# BL808 register map
File version: 0.1
Registers are access not given, no defined reset value unless marked. A register's access mark holds for its fields unless they carry their own. Offsets are from the block's base; [hi:lo] are bit positions; {n}, {i} and the like mark numbered series.

## DSP2
Base 0x30011000
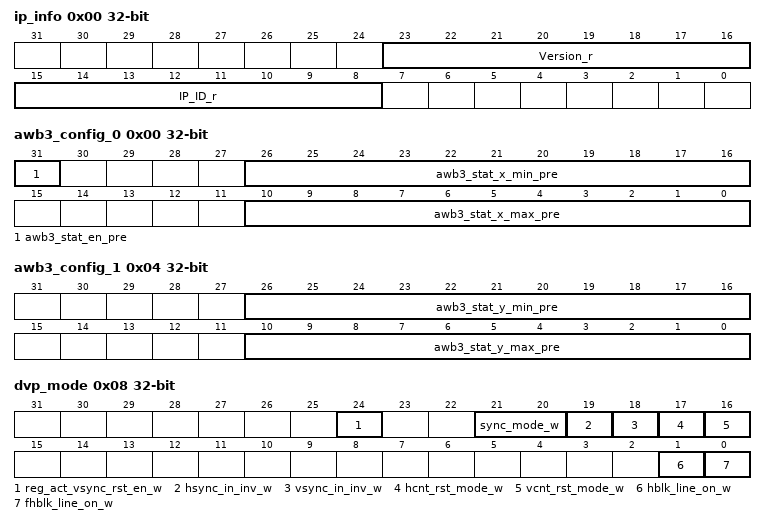
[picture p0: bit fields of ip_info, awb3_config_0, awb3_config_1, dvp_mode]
0x00 ip_info
  [23:16] Version_r ro, [15:8] IP_ID_r ro
0x00 awb3_config_0
  [31] awb3_stat_en_pre rw, [26:16] awb3_stat_x_min_pre rw, [10:0] awb3_stat_x_max_pre rw
0x04 awb3_config_1
  [26:16] awb3_stat_y_min_pre rw, [10:0] awb3_stat_y_max_pre rw
0x08 dvp_mode
  [24] reg_act_vsync_rst_en_w rw, [21:20] sync_mode_w rw, [19] hsync_in_inv_w rw, [18] vsync_in_inv_w rw, [17] hcnt_rst_mode_w rw, [16] vcnt_rst_mode_w rw, [1] hblk_line_on_w rw, [0] fhblk_line_on_w rw
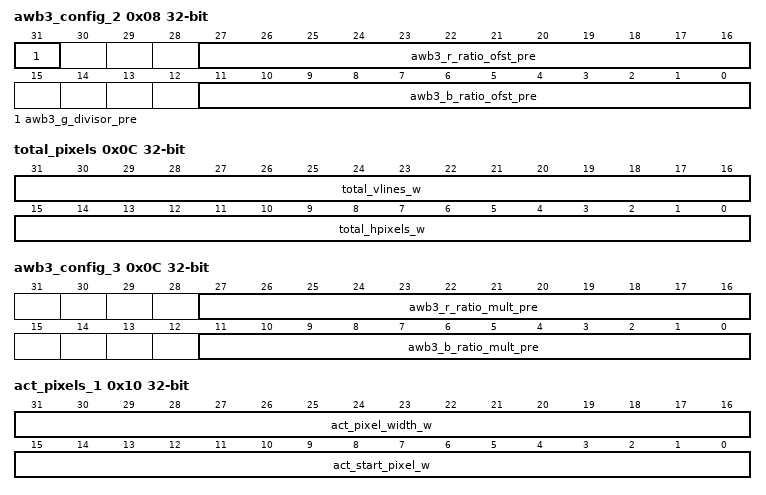
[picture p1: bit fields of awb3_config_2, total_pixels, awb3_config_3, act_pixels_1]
0x08 awb3_config_2
  [31] awb3_g_divisor_pre rw, [27:16] awb3_r_ratio_ofst_pre rw, [11:0] awb3_b_ratio_ofst_pre rw
0x0C total_pixels rw
  [31:16] total_vlines_w, [15:0] total_hpixels_w
0x0C awb3_config_3
  [27:16] awb3_r_ratio_mult_pre rw, [11:0] awb3_b_ratio_mult_pre rw
0x10 act_pixels_1 rw
  [31:16] act_pixel_width_w, [15:0] act_start_pixel_w
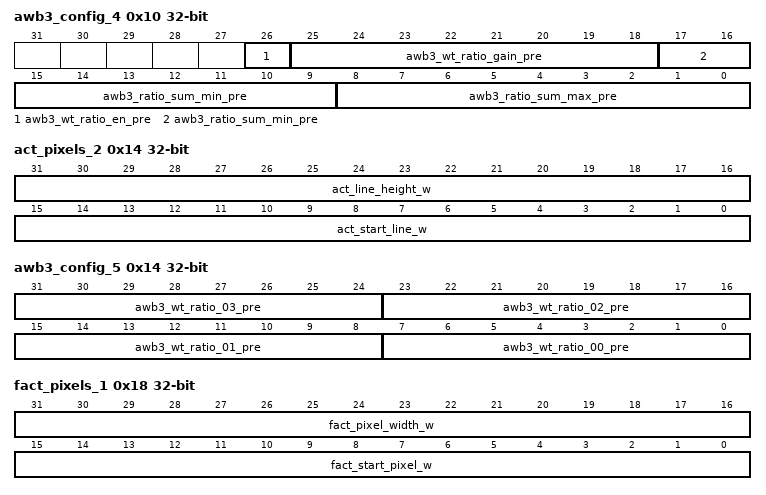
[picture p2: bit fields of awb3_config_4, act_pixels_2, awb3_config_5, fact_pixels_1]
0x10 awb3_config_4
  [26] awb3_wt_ratio_en_pre rw, [25:18] awb3_wt_ratio_gain_pre rw, [17:9] awb3_ratio_sum_min_pre rw, [8:0] awb3_ratio_sum_max_pre rw
0x14 act_pixels_2 rw
  [31:16] act_line_height_w, [15:0] act_start_line_w
0x14 awb3_config_5 rw
  [8n+7:8n] awb3_wt_ratio_{n:02}_pre (n=0..3)
0x18 fact_pixels_1 rw
  [31:16] fact_pixel_width_w, [15:0] fact_start_pixel_w
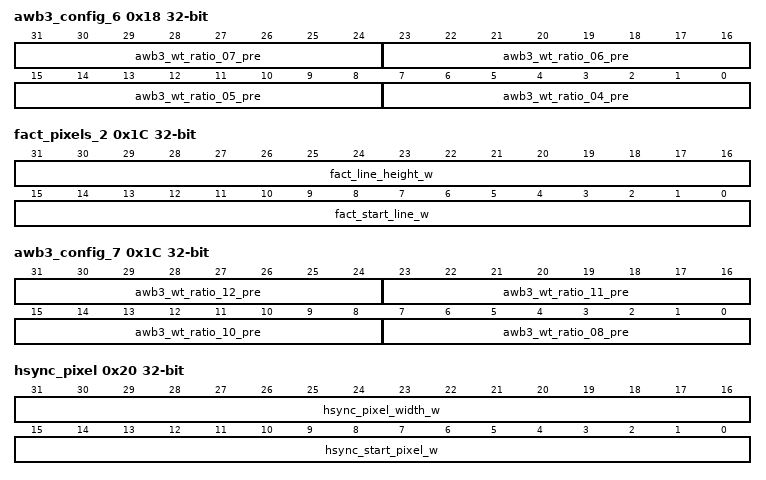
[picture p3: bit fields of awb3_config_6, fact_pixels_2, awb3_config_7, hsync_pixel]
0x18 awb3_config_6 rw
  [8n-25:8n-32] awb3_wt_ratio_{n:02}_pre (n=4..7)
0x1C fact_pixels_2 rw
  [31:16] fact_line_height_w, [15:0] fact_start_line_w
0x1C awb3_config_7 rw
  [31:24] awb3_wt_ratio_12_pre, [23:16] awb3_wt_ratio_11_pre, [15:8] awb3_wt_ratio_10_pre, [7:0] awb3_wt_ratio_08_pre
0x20 hsync_pixel rw
  [31:16] hsync_pixel_width_w, [15:0] hsync_start_pixel_w
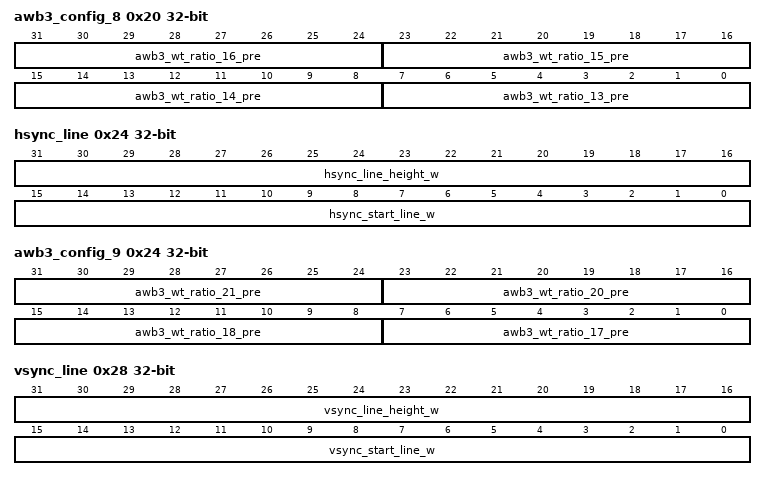
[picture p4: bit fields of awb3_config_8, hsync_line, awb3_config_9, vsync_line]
0x20 awb3_config_8 rw
  [8n-97:8n-104] awb3_wt_ratio_{n}_pre (n=13..16)
0x24 hsync_line rw
  [31:16] hsync_line_height_w, [15:0] hsync_start_line_w
0x24 awb3_config_9 rw
  [31:24] awb3_wt_ratio_21_pre, [23:16] awb3_wt_ratio_20_pre, [15:8] awb3_wt_ratio_18_pre, [7:0] awb3_wt_ratio_17_pre
0x28 vsync_line rw
  [31:16] vsync_line_height_w, [15:0] vsync_start_line_w
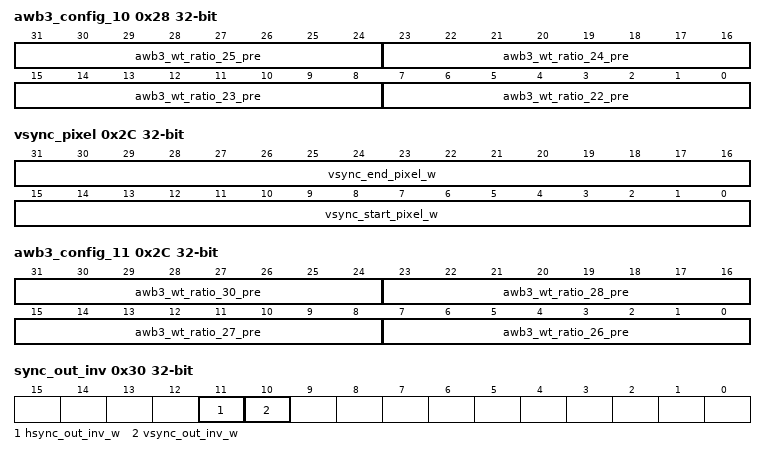
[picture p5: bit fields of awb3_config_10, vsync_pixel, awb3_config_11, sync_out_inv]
0x28 awb3_config_10 rw
  [8n-169:8n-176] awb3_wt_ratio_{n}_pre (n=22..25)
0x2C vsync_pixel rw
  [31:16] vsync_end_pixel_w, [15:0] vsync_start_pixel_w
0x2C awb3_config_11 rw
  [31:24] awb3_wt_ratio_30_pre, [23:16] awb3_wt_ratio_28_pre, [15:8] awb3_wt_ratio_27_pre, [7:0] awb3_wt_ratio_26_pre
0x30 sync_out_inv
  [11] hsync_out_inv_w rw, [10] vsync_out_inv_w rw
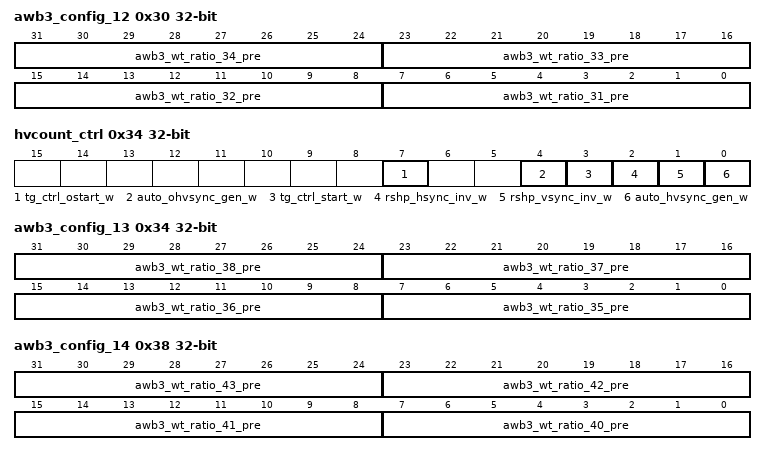
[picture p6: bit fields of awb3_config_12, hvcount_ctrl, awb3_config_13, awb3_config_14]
0x30 awb3_config_12 rw
  [8n-241:8n-248] awb3_wt_ratio_{n}_pre (n=31..34)
0x34 hvcount_ctrl
  [7] tg_ctrl_ostart_w write-once, [4] auto_ohvsync_gen_w rw, [3] tg_ctrl_start_w write-once, [2] rshp_hsync_inv_w rw, [1] rshp_vsync_inv_w rw, [0] auto_hvsync_gen_w rw
0x34 awb3_config_13 rw
  [8n-273:8n-280] awb3_wt_ratio_{n}_pre (n=35..38)
0x38 awb3_config_14 rw
  [8n-313:8n-320] awb3_wt_ratio_{n}_pre (n=40..43)
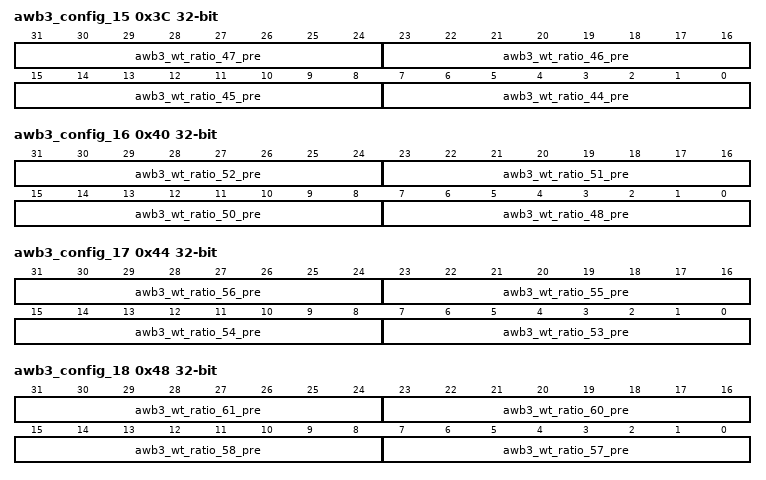
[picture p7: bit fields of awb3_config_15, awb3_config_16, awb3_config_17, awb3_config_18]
0x3C awb3_config_15 rw
  [8n-345:8n-352] awb3_wt_ratio_{n}_pre (n=44..47)
0x40 awb3_config_16 rw
  [31:24] awb3_wt_ratio_52_pre, [23:16] awb3_wt_ratio_51_pre, [15:8] awb3_wt_ratio_50_pre, [7:0] awb3_wt_ratio_48_pre
0x44 awb3_config_17 rw
  [8n-417:8n-424] awb3_wt_ratio_{n}_pre (n=53..56)
0x48 awb3_config_18 rw
  [31:24] awb3_wt_ratio_61_pre, [23:16] awb3_wt_ratio_60_pre, [15:8] awb3_wt_ratio_58_pre, [7:0] awb3_wt_ratio_57_pre
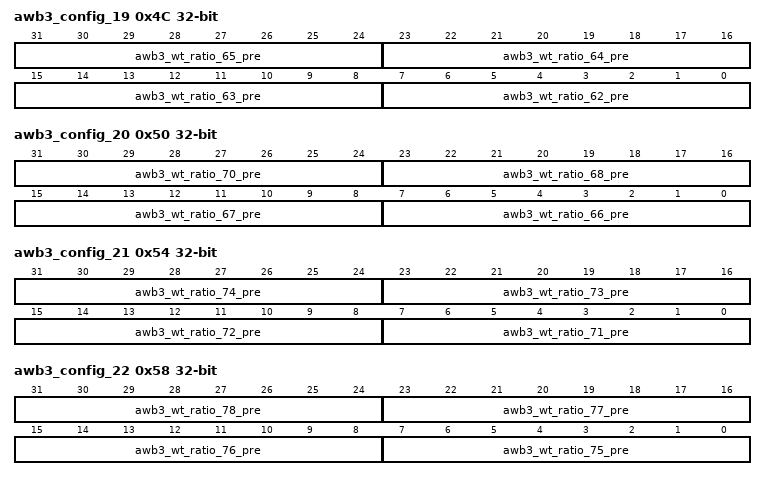
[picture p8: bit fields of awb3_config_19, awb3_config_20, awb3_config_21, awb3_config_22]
0x4C awb3_config_19 rw
  [8n-489:8n-496] awb3_wt_ratio_{n}_pre (n=62..65)
0x50 awb3_config_20 rw
  [31:24] awb3_wt_ratio_70_pre, [23:16] awb3_wt_ratio_68_pre, [15:8] awb3_wt_ratio_67_pre, [7:0] awb3_wt_ratio_66_pre
0x54 awb3_config_21 rw
  [8n-561:8n-568] awb3_wt_ratio_{n}_pre (n=71..74)
0x58 awb3_config_22 rw
  [8n-593:8n-600] awb3_wt_ratio_{n}_pre (n=75..78)
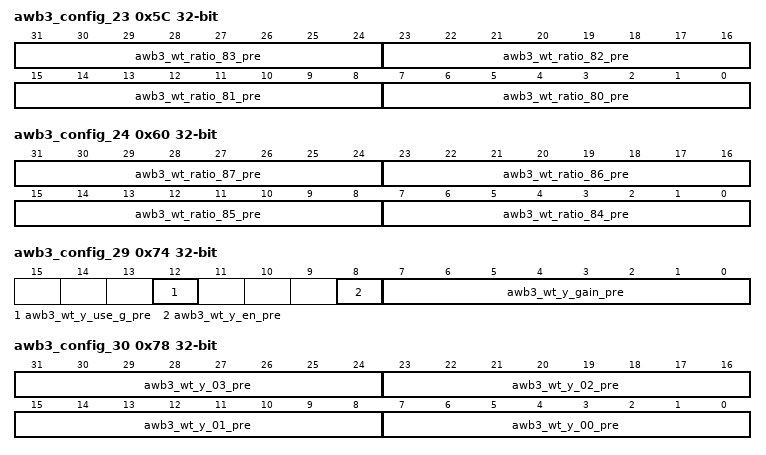
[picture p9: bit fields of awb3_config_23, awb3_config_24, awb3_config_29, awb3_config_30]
0x5C awb3_config_23 rw
  [8n-633:8n-640] awb3_wt_ratio_{n}_pre (n=80..83)
0x60 awb3_config_24 rw
  [8n-665:8n-672] awb3_wt_ratio_{n}_pre (n=84..87)
0x64 awb3_config_25
  [7:0] awb3_wt_ratio_88_pre rw
0x68 awb3_config_26
  [11:0] awb3_y_r_coeff_pre rw
0x6C awb3_config_27
  [11:0] awb3_y_g_coeff_pre rw
0x70 awb3_config_28
  [11:0] awb3_y_b_coeff_pre rw
0x74 awb3_config_29
  [12] awb3_wt_y_use_g_pre rw, [8] awb3_wt_y_en_pre rw, [7:0] awb3_wt_y_gain_pre rw
0x78 awb3_config_30 rw
  [8n+7:8n] awb3_wt_y_{n:02}_pre (n=0..3)
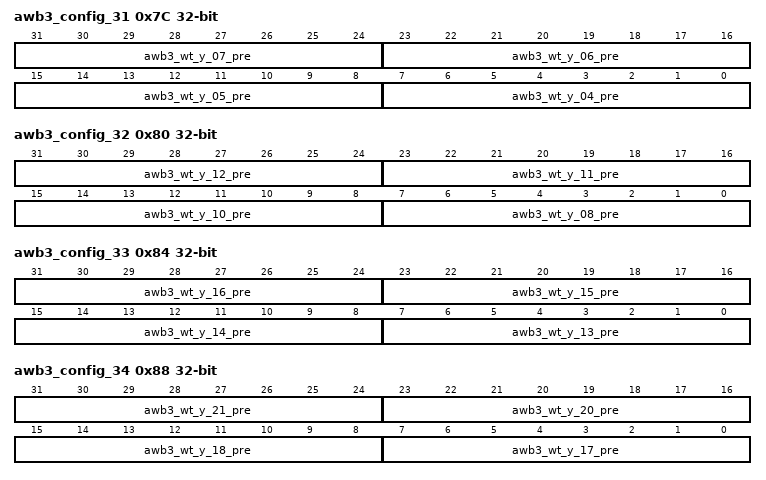
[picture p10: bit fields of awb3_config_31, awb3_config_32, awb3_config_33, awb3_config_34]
0x7C awb3_config_31 rw
  [8n-25:8n-32] awb3_wt_y_{n:02}_pre (n=4..7)
0x80 awb3_config_32 rw
  [31:24] awb3_wt_y_12_pre, [23:16] awb3_wt_y_11_pre, [15:8] awb3_wt_y_10_pre, [7:0] awb3_wt_y_08_pre
0x84 awb3_config_33 rw
  [8n-97:8n-104] awb3_wt_y_{n}_pre (n=13..16)
0x88 awb3_config_34 rw
  [31:24] awb3_wt_y_21_pre, [23:16] awb3_wt_y_20_pre, [15:8] awb3_wt_y_18_pre, [7:0] awb3_wt_y_17_pre
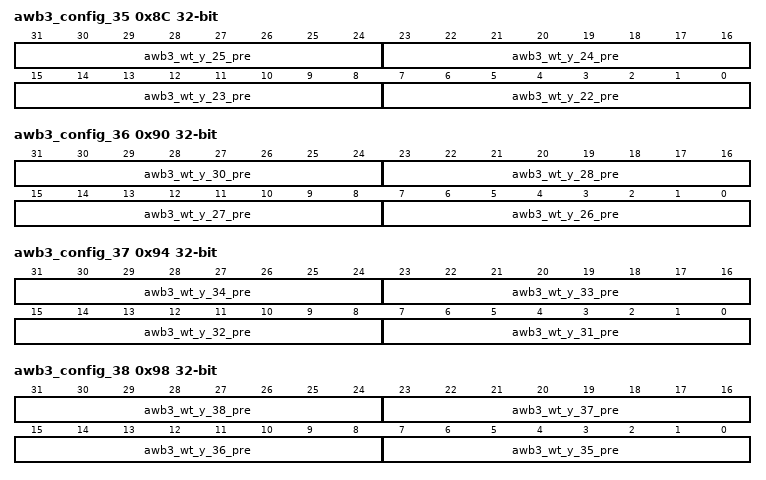
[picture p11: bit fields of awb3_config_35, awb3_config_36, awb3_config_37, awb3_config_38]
0x8C awb3_config_35 rw
  [8n-169:8n-176] awb3_wt_y_{n}_pre (n=22..25)
0x90 awb3_config_36 rw
  [31:24] awb3_wt_y_30_pre, [23:16] awb3_wt_y_28_pre, [15:8] awb3_wt_y_27_pre, [7:0] awb3_wt_y_26_pre
0x94 awb3_config_37 rw
  [8n-241:8n-248] awb3_wt_y_{n}_pre (n=31..34)
0x98 awb3_config_38 rw
  [8n-273:8n-280] awb3_wt_y_{n}_pre (n=35..38)
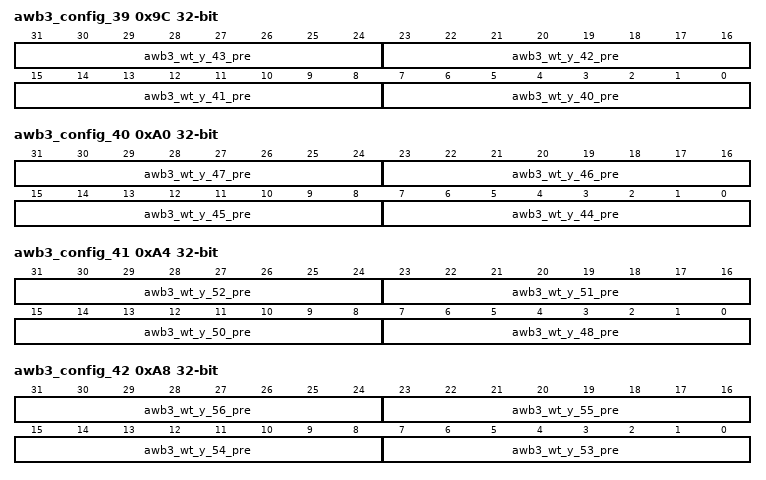
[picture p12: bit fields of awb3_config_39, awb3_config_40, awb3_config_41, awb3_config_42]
0x9C awb3_config_39 rw
  [8n-313:8n-320] awb3_wt_y_{n}_pre (n=40..43)
0xA0 awb3_config_40 rw
  [8n-345:8n-352] awb3_wt_y_{n}_pre (n=44..47)
0xA4 awb3_config_41 rw
  [31:24] awb3_wt_y_52_pre, [23:16] awb3_wt_y_51_pre, [15:8] awb3_wt_y_50_pre, [7:0] awb3_wt_y_48_pre
0xA8 awb3_config_42 rw
  [8n-417:8n-424] awb3_wt_y_{n}_pre (n=53..56)
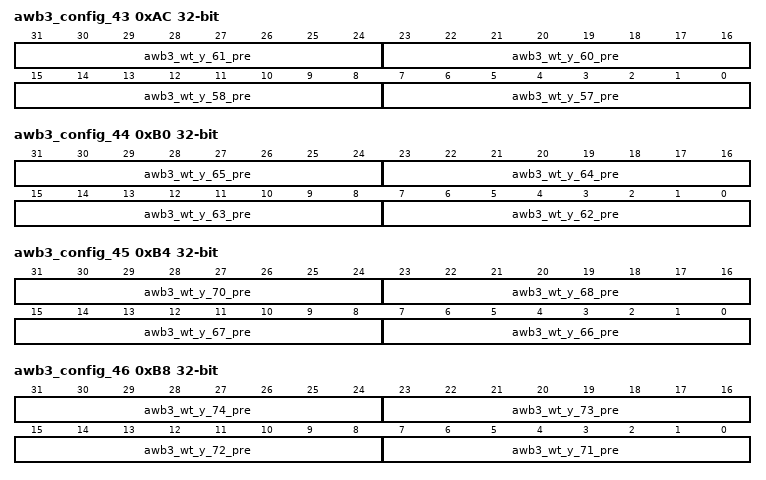
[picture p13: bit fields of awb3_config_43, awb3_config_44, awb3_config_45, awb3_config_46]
0xAC awb3_config_43 rw
  [31:24] awb3_wt_y_61_pre, [23:16] awb3_wt_y_60_pre, [15:8] awb3_wt_y_58_pre, [7:0] awb3_wt_y_57_pre
0xB0 awb3_config_44 rw
  [8n-489:8n-496] awb3_wt_y_{n}_pre (n=62..65)
0xB4 awb3_config_45 rw
  [31:24] awb3_wt_y_70_pre, [23:16] awb3_wt_y_68_pre, [15:8] awb3_wt_y_67_pre, [7:0] awb3_wt_y_66_pre
0xB8 awb3_config_46 rw
  [8n-561:8n-568] awb3_wt_y_{n}_pre (n=71..74)
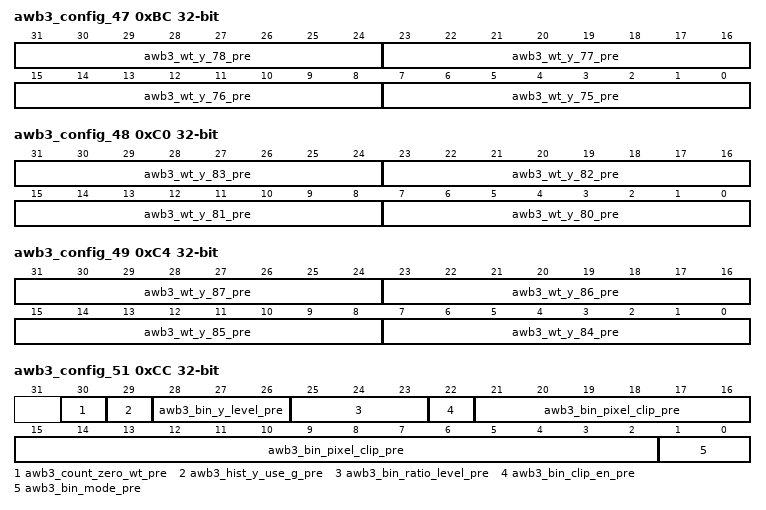
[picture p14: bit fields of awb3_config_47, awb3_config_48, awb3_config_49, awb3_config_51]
0xBC awb3_config_47 rw
  [8n-593:8n-600] awb3_wt_y_{n}_pre (n=75..78)
0xC0 awb3_config_48 rw
  [8n-633:8n-640] awb3_wt_y_{n}_pre (n=80..83)
0xC4 awb3_config_49 rw
  [8n-665:8n-672] awb3_wt_y_{n}_pre (n=84..87)
0xC8 awb3_config_50
  [7:0] awb3_wt_y_88_pre rw
0xCC awb3_config_51
  [30] awb3_count_zero_wt_pre rw, [29] awb3_hist_y_use_g_pre rw, [28:26] awb3_bin_y_level_pre rw, [25:23] awb3_bin_ratio_level_pre rw, [22] awb3_bin_clip_en_pre rw, [21:2] awb3_bin_pixel_clip_pre rw, [1:0] awb3_bin_mode_pre rw
0xD0 awb3_config_52
  [5:4] awb3_ink_type_pre rw, [3:0] awb3_ink_gain_pre rw
0xD4 awb3_sta_0 ro
  [31:0] awb3_r_sum0_r
0xD8 awb3_sta_1 ro
  [31:0] awb3_g_sum0_r
0xDC awb3_sta_2 ro
  [31:0] awb3_b_sum0_r
0xE0 awb3_sta_3 ro
  [31:0] awb3_r_sum_hex0_r
0xE4 awb3_sta_4 ro
  [31:0] awb3_g_sum_hex0_r
0xE8 awb3_sta_5 ro
  [31:0] awb3_b_sum_hex0_r
0xEC awb3_sta_6
  [19:0] awb3_pixel_hex0_r ro
0xF0 awb3_sta_7
  [7:0] awb3_r_ratio_hex_y0u_r ro
0xF4 awb3_sta_8 ro
  [31:0] awb3_r_ratio_hex_y0l_r
0xF8 awb3_sta_9
  [7:0] awb3_b_ratio_hex_y0u_r ro
0xFC dsp2_apb_ctrl
  [15:0] rg_pclk_force_on_w rw
0xFC awb3_sta_10 ro
  [31:0] awb3_b_ratio_hex_y0l_r
0x100 awb3_sta_11
  [27:0] awb3_wt_hex_y0_r ro
0x104 awb3_sta_12
  [19:0] awb3_pixel_hex_y0_r ro
0x108 awb3_sta_13
  [7:0] awb3_r_ratio_hist0u_r ro
0x10C awb3_sta_14 ro
  [31:0] awb3_r_ratio_hist0l_r
0x110 pattern_mode
  [31:16] act_hsize_w rw, [10] reg_bl_lpid_sel_w rw, [9] lid_inv_rgb_pre rw, [8] pid_inv_rgb_pre rw, [2:0] pattern_mode_w rw
0x110 awb3_sta_15
  [7:0] awb3_b_ratio_hist0u_r ro
0x114 clamp_R_Gr rw
  [31:16] clp_Gr_pre, [15:0] clp_R_pre
0x114 awb3_sta_16 ro
  [31:0] awb3_b_ratio_hist0l_r
0x118 clamp_B_Gb rw
  [31:16] clp_B_pre, [15:0] clp_Gb_pre
0x118 awb3_sta_17
  [27:0] awb3_wt_hist0_r ro
0x11C awb3_sta_18
  [19:0] awb3_pixel_hist0_r ro
0x120 awb3_sta_19
  [7:0] awb3_r_ratio_hist_clip0u_r ro
0x124 awb3_sta_20 ro
  [31:0] awb3_r_ratio_hist_clip0l_r
0x128 awb3_sta_21
  [7:0] awb3_b_ratio_hist_clip0u_r ro
0x12C awb3_sta_22 ro
  [31:0] awb3_b_ratio_hist_clip0l_r
0x130 ob_win rw
  [31:16] ob_win_starty_w, [15:0] ob_win_startx_w
0x130 awb3_sta_23
  [27:0] awb3_wt_hist_clip0_r ro
0x134 black_columns_bit
  [7:4] black_columns_bit_w rw, [3:0] black_rows_bit_w rw
0x134 awb3_sta_24
  [19:0] awb3_pixel_hist_clip0_r ro
0x138 Ob_R_Gr ro
  [31:16] Ob_Gr_r, [15:0] Ob_R_r
0x138 awb3_sta_25 ro
  [31:0] awb3_r_sum1_r
0x13C Ob_B_Gb ro
  [31:16] Ob_B_r, [15:0] Ob_Gb_r
0x13C awb3_sta_26 ro
  [31:0] awb3_g_sum1_r
0x140 awb3_sta_27 ro
  [31:0] awb3_b_sum1_r
0x144 awb3_sta_28 ro
  [31:0] awb3_r_sum_hex1_r
0x148 awb3_sta_29 ro
  [31:0] awb3_g_sum_hex1_r
0x14C awb3_sta_30 ro
  [31:0] awb3_b_sum_hex1_r
0x150 gain_R_G
  [26:16] ggain1_pre rw, [10:0] rgain1_pre rw
0x150 awb3_sta_31
  [19:0] awb3_pixel_hex1_r ro
0x154 gain_B
  [10:0] bgain1_pre rw
0x154 awb3_sta_32
  [7:0] awb3_r_ratio_hex_y1u_r ro
0x158 awb3_sta_33 ro
  [31:0] awb3_r_ratio_hex_y1l_r
0x15C awb3_sta_34
  [7:0] awb3_b_ratio_hex_y1u_r ro
0x160 awb3_sta_35 ro
  [31:0] awb3_b_ratio_hex_y1l_r
0x164 awb3_sta_36
  [27:0] awb3_wt_hex_y1_r ro
0x168 awb3_sta_37
  [19:0] awb3_pixel_hex_y1_r ro
0x16C awb3_sta_38
  [7:0] awb3_r_ratio_hist1u_r ro
0x170 awb3_sta_39 ro
  [31:0] awb3_r_ratio_hist1l_r
0x174 awb3_sta_40
  [7:0] awb3_b_ratio_hist1u_r ro
0x178 awb3_sta_41 ro
  [31:0] awb3_b_ratio_hist1l_r
0x17C awb3_sta_42
  [27:0] awb3_wt_hist1_r ro
0x180 awb3_sta_43
  [19:0] awb3_pixel_hist1_r ro
0x184 awb3_sta_44
  [7:0] awb3_r_ratio_hist_clip1u_r ro
0x188 awb3_sta_45 ro
  [31:0] awb3_r_ratio_hist_clip1l_r
0x18C awb3_sta_46
  [16:0] awb3_b_ratio_hist_clip1u_r ro
0x190 awb3_sta_47 ro
  [31:0] awb3_b_ratio_hist_clip1l_r
0x194 awb3_sta_48
  [27:0] awb3_wt_hist_clip1_r ro
0x198 awb3_sta_49
  [19:0] awb3_pixel_hist_clip1_r ro
0x19C awb3_status_0
  [8] awb3_buf_idx_r ro, [4:0] awb3_w_cnt_r ro
0x1D0 clp_rgr_gain
  [31] clp_gain_en_pre rw, [30:16] clp_r_gain_pre rw, [14:0] clp_gr_gain_pre rw
0x1D4 clp_bgb_gain
  [30:16] clp_b_gain_pre rw, [14:0] clp_gb_gain_pre rw
0x1F0 Image_select
  [1:0] Image_Select_pre rw
0x224 LSC_setting
  [31:24] Y_offset_w rw, [23:16] X_offset_w rw, [8] Lsc_on_w rw
0x228 LSC_coeff_R_A
  [22:0] R_Acoeff_w rw
0x22C LSC_coeff_R_BE
  [28:16] R_Ecoeff_w rw, [12:0] R_Bcoeff_w rw
0x230 LSC_coeff_R_CD
  [31:24] R_Ccoeff_w rw, [22:0] R_Dcoeff_w rw
0x234 LSC_coeff_R_G
  [22:0] R_Gcoeff_w rw
0x238 LSC_coeff_G_A
  [22:0] G_Acoeff_w rw
0x23C LSC_coeff_G_BE
  [28:16] G_Ecoeff_w rw, [12:0] G_Bcoeff_w rw
0x240 LSC_coeff_G_CD
  [31:24] G_Ccoeff_w rw, [22:0] G_Dcoeff_w rw
0x244 LSC_coeff_G_G
  [22:0] G_Gcoeff_w rw
0x248 LSC_coeff_B_A
  [22:0] B_Acoeff_w rw
0x24C LSC_coeff_B_BE
  [28:16] B_Ecoeff_w rw, [12:0] B_Bcoeff_w rw
0x250 LSC_coeff_B_CD
  [31:24] B_Ccoeff_w rw, [22:0] B_Dcoeff_w rw
0x254 LSC_coeff_B_G
  [22:0] B_Gcoeff_w rw
0x258 MAX_R_G rw
  [31:16] MAXG_w, [15:0] MAXR_w
0x25C MAX_B
  [15:0] MAXB_w rw
0x260 defect_setting
  [23:16] defect_address_w rw, [10] resolution_enhance3_w rw, [9] resolution_enhance2_w rw, [8] resolution_enhance1_w rw, [2:0] defect_correct_mode_w rw
0x264 defect_position rw
  [31:16] y_position_w, [15:0] x_position_w
0x268 defect_th_A rw
  [8n-1:8n-8] defect_th{n}_w (n=1..4)
0x26C defect_th_B
  [7:0] defect_th5_w rw
0x270 awb_setting
  [26:16] grid_cnt_within_thre_r ro, [3] bl_digital_gain_sel_w rw, [2] bl_awb_gain_sel_w rw, [1] new_awb_sta_enable_w rw, [0] awb_switch_bank_en_w rw
0x274 awb_roi_x
  [26:16] awb_roi_width_w rw, [10:0] awb_roi_start_x_w rw
0x278 awb_roi_y
  [26:16] awb_roi_height_w rw, [10:0] awb_roi_start_y_w rw
0x27C awb_image_size
  [26:16] awb_image_height_w rw, [10:0] awb_image_width_w rw
0x280 awb_grid_size
  [29:24] awb_grid_y_max_w rw, [21:16] awb_grid_x_max_w rw, [15:8] awb_grid_height_w rw, [7:0] awb_grid_width_w rw
0x284 awb_r_thre
  [27:16] awb_r_min_thr_w rw, [11:0] awb_r_max_thr_w rw
0x288 awb_g_thre
  [27:16] awb_g_min_thr_w rw, [11:0] awb_g_max_thr_w rw
0x28C awb_b_thre
  [27:16] awb_b_min_thr_w rw, [11:0] awb_b_max_thr_w rw
0x290 awb_rgr_gain rw
  [31:16] awb_r_gain_pre, [15:0] awb_gr_gain_pre
0x294 awb_bgb_gain rw
  [31:16] awb_b_gain_pre, [15:0] awb_gb_gain_pre
0x298 awb_rgr_offset
  [27:16] awb_r_offset_pre rw, [11:0] awb_gr_offset_pre rw
0x29C awb_bgb_offset
  [27:16] awb_b_offset_pre rw, [11:0] awb_gb_offset_pre rw
0x2A0 cfa_int_1
  [0] reg_cfa_fringe_on_w rw
0x2A8 digital_rgr_gain rw
  [31:16] digital_r_gain_pre, [15:0] digital_gr_gain_pre
0x2AC digital_bgb_gain rw
  [31:16] digital_b_gain_pre, [15:0] digital_gb_gain_pre
0x2BC ae_roi_x
  [26:16] ae_roi_width_pre rw, [10:0] ae_roi_start_x_pre rw
0x2C0 ae_roi_y
  [26:16] ae_roi_height_pre rw, [10:0] ae_roi_start_y_pre rw
0x2C4 ae_image_size
  [26:16] ae_image_height_pre rw, [10:0] ae_image_width_pre rw
0x2C8 ae_grid_size
  [28] ae_hist_roi_en_pre rw, [27] ae_hist_mode_pre rw, [26] ae_hist_en_pre rw, [25] ae_switch_bank_en_pre rw, [24] new_ae_sta_enable_w rw, [23:20] ae_grid_x_max_pre rw, [19:16] ae_grid_y_max_pre rw, [15:8] ae_grid_height_pre rw, [7:0] ae_grid_width_pre rw
0x2CC ae_coeff
  [23:16] ae_ysum_coeff_b_pre rw, [15:8] ae_ysum_coeff_g_pre rw, [7:0] ae_ysum_coeff_r_pre rw
0x2D0 ae2_roi_x
  [26:16] ae_hist_x_min_pre rw, [10:0] ae_hist_x_max_pre rw
0x2D4 ae2_roi_y
  [26:16] ae_hist_y_min_pre rw, [10:0] ae_hist_y_max_pre rw
0x2E8 ae_status
  [24:20] blae_w_cnt_r ro, [16] blae_buf_idx_r ro, [8:4] ae_hist_w_cnt_r ro
0x2EC ae_sta_dbg
  [30] ae_fifo_empty ro, [29] ae_operation_done ro, [28:25] ae_control_status ro, [24] ae_fifo_full ro, [23:17] ae_grid_cnt_max ro, [16] ae_sta_int_flag ro, [15:8] ae_write_data_cnt ro, [7] ae_sta_done ro, [6:0] ae_grid_cnt ro
0x2F4 awb_sta_dbg1
  [31] blawb_buf_idx_r ro, [28:24] blawb_w_cnt_r ro, [21] awb_fifo_empty ro, [20] awb_operation_done ro, [19:16] awb_control_status ro, [12] awb_fifo_full ro, [10:0] awb_grid_cnt_max ro
0x2F8 awb_sta_dbg0
  [28] awb_sta_int_flag ro, [27:16] awb_write_data_cnt ro, [12] awb_sta_done ro, [9:0] awb_grid_cnt ro
0x2FC dummy rw
0x314 ccr_coef_A
  [27:16] a11_pre rw
0x318 ccr_coef_B
  [27:16] a13_pre rw, [11:0] a12_pre rw
0x31C ccr_coef_C
  [27:16] a22_pre rw, [11:0] a21_pre rw
0x320 ccr_coef_D
  [27:16] a31_pre rw, [11:0] a23_pre rw
0x324 ccr_coef_E
  [27:16] a33_pre rw, [11:0] a32_pre rw
0x328 gamma_A
  [4] bl_gamma_en_pre rw, [1] gamma_eb_pre rw, [0] gamma_on_pre rw
0x33C conv_mode
  [0] conv_mode_w rw
0x34C YUVC_A rw
  [31:24] CrSaturation_pre, [23:16] CbSaturation_pre, [15:8] YContrast_w, [7:0] YBrightness_w
0x350 YUVC_B
  [31:24] SolarThred_w rw, [23:16] SepiaCr_w rw, [15:8] SepiaCb_w rw, [4] C444to422Filteringmode_w rw, [2:0] SpecialMode_w rw
0x354 DNR_A
  [31:28] Filt_Strength_3D_pre rw, [27:24] Filt_Strength_2D_pre rw, [23:8] nr_hsize_pre rw, [5:0] noise_level_pre rw
0x358 DNR_B
  [10:9] out_format_w rw, [8] CbCr_select_w rw
0x360 BLEE_0
  [24:16] txt_thr_pre rw, [1] ovrsht_eb_pre rw, [0] ee_eb_pre rw
0x364 BLEE_1
  [23:16] flat_thr_pre rw, [14:8] thresh2_pre rw, [6:0] thresh1_pre rw
0x368 BLEE_2
  [30:24] negee_str_pre rw, [22:16] posee_str_pre rw, [14:8] ovrsht_neg_pre rw, [6:0] ovrsht_pos_pre rw
0x36C BLEE_3
  [23:16] nr_str_pre rw, [15:0] edge_thr_pre rw
{0x360+4i} BLEE_{i} (i=4..9)
  [25:16] luma_wgt{2i-7}_pre rw, [9:0] luma_wgt{2i-8}_pre rw
0x388 BLEE_A
  [25:16] luma_wgt13_pre rw, [9:0] luma_wgt12_pre rw
0x38C BLEE_B
  [25:16] luma_wgt15_pre rw, [9:0] luma_wgt14_pre rw
0x390 BLEE_C
  [25:16] luma_wgt17_pre rw, [9:0] luma_wgt16_pre rw
0x394 BLEE_D
  [25:16] luma_wgt19_pre rw, [9:0] luma_wgt18_pre rw
0x398 BLEE_E
  [25:16] luma_wgt21_pre rw, [9:0] luma_wgt20_pre rw
0x39C BLEE_F
  [25:16] luma_wgt23_pre rw, [9:0] luma_wgt22_pre rw
{0x378+4i} BLEE_{i} (i=10..13)
  [25:16] luma_wgt{2i+5}_pre rw, [9:0] luma_wgt{2i+4}_pre rw
0x3B0 CS1
  [24:16] cs1_gain_pre rw, [12:8] cs1_weight_pre rw, [4] cs1_enable_pre rw, [3:0] cs1_grey_th_pre rw
0x3B4 CS2
  [24:16] cs2_gain_pre rw, [12:8] cs2_weight_pre rw, [4] cs2_enable_pre rw, [3:0] cs2_grey_th_pre rw
0x3FC DUMMY_CTRL
  [0] reg_bl444to422_en_w rw
0x444 afwas
  [31:24] afwasy_w rw, [23:16] afwasx_w rw
0x448 afwae_afwbs rw
  [31:24] afwbsy_w, [23:16] afwbsx_w, [15:8] afwaey_w, [7:0] afwaex_w
0x44C afbae_afmisc rw
  [31:30] sum_shift_a_w, [29:27] sum_shift_b_w, [26:24] AFGamma_w, [23:20] fcore1_w, [19:16] fcore2_w, [15:8] afwbey_w, [7:0] afwbex_w
0x450 afwah ro
  [31:16] afwah2_r, [15:0] afwah1_r
0x454 afwbh ro
  [31:16] afwbh2_r, [15:0] afwbh1_r
0x500 blae_read_grid_addr
  [24:20] blae_w_cnt ro, [16] blae_buf_idx ro, [8:0] blae_read_grid_addr rw
0x500 awb2_sta_xaxis
  [26:16] awb2_x_max_pre rw, [10:0] awb2_x_min_pre rw
0x504 blae_grid_data ro
  [31:0] blae_grid_data
0x504 awb2_sta_yaxis
  [26:16] awb2_y_max_pre rw, [10:0] awb2_y_min_pre rw
0x508 awb2_sta_pixel_num
  [20:0] awb2_pixel_num_pre rw
0x50C awb2_sta_gain0 rw
  [31:16] awb2_stat_rgain_pre, [15:0] awb2_stat_ggain_pre
0x510 awb2_sta_gain1 rw
  [31:16] awb2_stat_bgain_pre, [15:0] awb2_rgain_pre
0x514 awb2_sta_gain2 rw
  [31:16] awb2_ggain_pre, [15:0] awb2_bgain_pre
0x518 awb2_sta_gain3
  [25:16] awb2_ugain_pre rw, [9:0] awb2_vgain_pre rw
0x51C awb2_sta_l0 rw
  [8n-1:8n-8] awb2_yth{n}_pre (n=1..4)
0x520 awb2_sta_l1 rw
  [31:24] awb2_yth0_pre, [23:16] awb2_yweight4_pre, [15:8] awb2_yweight3_pre, [7:0] awb2_yweight2_pre
0x524 awb2_sta_l2
  [31:24] awb2_yweight1_pre rw, [23:16] awb2_yweight0_pre rw, [8:0] awb2_yslope4_pre rw
0x528 awb2_sta_l3
  [24:16] awb2_yslope3_pre rw, [8:0] awb2_yslope2_pre rw
0x52C awb2_sta_l4
  [24:16] awb2_yslope1_pre rw, [8:0] awb2_yslope0_pre rw
0x530 awb2_sta_c0 rw
  [8n-25:8n-32] awb2_ureg{n}_pre (n=4..7)
0x534 awb2_sta_c1 rw
  [8n+7:8n] awb2_ureg{n}_pre (n=0..3)
0x538 awb2_sta_c2 rw
  [8n-25:8n-32] awb2_vreg{n}_pre (n=4..7)
0x53C awb2_sta_c3 rw
  [8n+7:8n] awb2_vreg{n}_pre (n=0..3)
0x540 awb2_sta_c4
  [8n-27:8n-32] awb2_cth{n}_pre rw (n=4..7)
0x544 awb2_sta_c5
  [8n+5:8n] awb2_cth{n}_pre rw (n=0..3)
0x548 awb2_sta_c6 rw
  [8n-25:8n-32] awb2_cslope{n}_pre (n=4..7)
0x54C awb2_sta_c7 rw
  [8n+7:8n] awb2_cslope{n}_pre (n=0..3)
0x550 awb2_sta_r0
  [27:16] awb2_r_avg0_r ro, [11:0] awb2_g_avg0_r ro
0x554 awb2_sta_r1
  [27:16] awb2_b_avg0_r ro, [14:0] awb2_white_ratio0_r ro
0x558 awb2_sta_r2
  [27:16] awb2_r_avg1_r ro, [11:0] awb2_g_avg1_r ro
0x55C awb2_sta_r3
  [27:16] awb2_b_avg1_r ro, [14:0] awb2_white_ratio1_r ro
0x560 awb2_sta_r4 ro
  [31:0] awb2_whiter_sumh0_r
0x564 awb2_sta_r5
  [24:16] awb2_whiter_suml0_r ro, [8:0] awb2_whiter_suml1_r ro
0x568 awb2_sta_r6 ro
  [31:0] awb2_whiter_sumh1_r
0x56C awb2_sta_r7 ro
  [31:0] awb2_whiteg_sumh0_r
0x570 awb2_sta_r8
  [24:16] awb2_whiteg_suml0_r ro, [8:0] awb2_whiteg_suml1_r ro
0x574 awb2_sta_r9 ro
  [31:0] awb2_whiteg_sumh1_r
0x578 awb2_sta_ra ro
  [31:0] awb2_whiteb_sumh0_r
0x57C awb2_sta_rb
  [24:16] awb2_whiteb_suml0_r ro, [8:0] awb2_whiteb_suml1_r ro
0x580 awb2_sta_rc ro
  [31:0] awb2_whiteb_sumh1_r
0x584 awb2_sta_int
  [12:8] awb2_w_cnt_r ro, [2] awb2_buf_idx_r ro, [1] awb2_stat_en_pre rw, [0] awb2_gain_en_pre rw
0x600 blawb_read_grid_addr
  [24:20] blawb_w_cnt ro, [16] blawb_buf_idx ro, [11:0] blawb_read_grid_addr rw
0x600 bnr_config_0
  [25:16] th_base_b_pre rw, [12:8] lpf_weight_pre rw, [7] bnr_en_pre rw, [6:0] bnr_weight_pre rw
0x604 blawb_grid_data ro
  [31:0] blawb_grid_data
0x604 bnr_config_1
  [25:16] th_base_g_pre rw, [9:0] th_base_r_pre rw
0x608 bnr_config_2
  [29:24] slope_gain_pre rw, [23:16] th_slope_b_pre rw, [15:8] th_slope_g_pre rw, [7:0] th_slope_r_pre rw
0x60C bnr_config_3
  [12:8] fb_lpf_weight_pre rw, [2:0] fb_level_pre rw
0x700 GAMMA_CRUVE_1 rw
  [8n+7:8n] c{n}_pre (n=0..3)
0x704 GAMMA_CRUVE_2 rw
  [8n-25:8n-32] c{n}_pre (n=4..7)
0x708 GAMMA_CRUVE_3 rw
  [8n-57:8n-64] c{n}_pre (n=8..11)
0x70C GAMMA_CRUVE_4 rw
  [8n-89:8n-96] c{n}_pre (n=12..15)
0x710 GAMMA_CRUVE_5 rw
  [8n-121:8n-128] c{n}_pre (n=16..19)
0x714 GAMMA_CRUVE_6 rw
  [8n-153:8n-160] c{n}_pre (n=20..23)
0x718 GAMMA_CRUVE_7 rw
  [8n-185:8n-192] c{n}_pre (n=24..27)
0x71C GAMMA_CRUVE_8 rw
  [8n-217:8n-224] c{n}_pre (n=28..31)
0x720 GAMMA_CRUVE_9 rw
  [8n-249:8n-256] c{n}_pre (n=32..35)
0x724 GAMMA_CRUVE_10 rw
  [8n-281:8n-288] c{n}_pre (n=36..39)
0x728 GAMMA_CRUVE_11 rw
  [8n-313:8n-320] c{n}_pre (n=40..43)
0x72C GAMMA_CRUVE_12 rw
  [8n-345:8n-352] c{n}_pre (n=44..47)
0x730 GAMMA_CRUVE_13 rw
  [8n-377:8n-384] c{n}_pre (n=48..51)
0x734 GAMMA_CRUVE_14 rw
  [8n-409:8n-416] c{n}_pre (n=52..55)
0x738 GAMMA_CRUVE_15 rw
  [8n-441:8n-448] c{n}_pre (n=56..59)
0x73C GAMMA_CRUVE_16 rw
  [8n-473:8n-480] c{n}_pre (n=60..63)
0x740 GAMMA_CRUVE_17 rw
  [8n-505:8n-512] c{n}_pre (n=64..67)
0x744 GAMMA_CRUVE_18 rw
  [8n-537:8n-544] c{n}_pre (n=68..71)
0x748 GAMMA_CRUVE_19 rw
  [8n-569:8n-576] c{n}_pre (n=72..75)
0x74C GAMMA_CRUVE_20 rw
  [8n-601:8n-608] c{n}_pre (n=76..79)
0x750 GAMMA_CRUVE_21 rw
  [8n-633:8n-640] c{n}_pre (n=80..83)
0x754 GAMMA_CRUVE_22 rw
  [8n-665:8n-672] c{n}_pre (n=84..87)
0x758 GAMMA_CRUVE_23 rw
  [8n-697:8n-704] c{n}_pre (n=88..91)
0x75C GAMMA_CRUVE_24 rw
  [8n-729:8n-736] c{n}_pre (n=92..95)
0x760 GAMMA_CRUVE_25 rw
  [8n-761:8n-768] c{n}_pre (n=96..99)
0x764 GAMMA_CRUVE_26 rw
  [8n-793:8n-800] c{n}_pre (n=100..103)
0x768 GAMMA_CRUVE_27 rw
  [8n-825:8n-832] c{n}_pre (n=104..107)
0x76C GAMMA_CRUVE_28 rw
  [8n-857:8n-864] c{n}_pre (n=108..111)
0x770 GAMMA_CRUVE_29 rw
  [8n-889:8n-896] c{n}_pre (n=112..115)
0x774 GAMMA_CRUVE_30 rw
  [8n-921:8n-928] c{n}_pre (n=116..119)
0x778 GAMMA_CRUVE_31 rw
  [8n-953:8n-960] c{n}_pre (n=120..123)
0x77C GAMMA_CRUVE_32 rw
  [8n-985:8n-992] c{n}_pre (n=124..127)
0x780 GAMMA_CRUVE_33 rw
  [8n-1017:8n-1024] c{n}_pre (n=128..131)
0x784 GAMMA_CRUVE_34 rw
  [8n-1049:8n-1056] c{n}_pre (n=132..135)
0x788 GAMMA_CRUVE_35 rw
  [8n-1081:8n-1088] c{n}_pre (n=136..139)
0x78C GAMMA_CRUVE_36 rw
  [8n-1113:8n-1120] c{n}_pre (n=140..143)
0x790 GAMMA_CRUVE_37 rw
  [8n-1145:8n-1152] c{n}_pre (n=144..147)
0x794 GAMMA_CRUVE_38 rw
  [8n-1177:8n-1184] c{n}_pre (n=148..151)
0x798 GAMMA_CRUVE_39 rw
  [8n-1209:8n-1216] c{n}_pre (n=152..155)
0x79C GAMMA_CRUVE_40 rw
  [8n-1241:8n-1248] c{n}_pre (n=156..159)
0x7A0 GAMMA_CRUVE_41 rw
  [8n-1273:8n-1280] c{n}_pre (n=160..163)
0x7A4 GAMMA_CRUVE_42 rw
  [8n-1305:8n-1312] c{n}_pre (n=164..167)
0x7A8 GAMMA_CRUVE_43 rw
  [8n-1337:8n-1344] c{n}_pre (n=168..171)
0x7AC GAMMA_CRUVE_44 rw
  [8n-1369:8n-1376] c{n}_pre (n=172..175)
0x7B0 GAMMA_CRUVE_45 rw
  [8n-1401:8n-1408] c{n}_pre (n=176..179)
0x7B4 GAMMA_CRUVE_46 rw
  [8n-1433:8n-1440] c{n}_pre (n=180..183)
0x7B8 GAMMA_CRUVE_47 rw
  [8n-1465:8n-1472] c{n}_pre (n=184..187)
0x7BC GAMMA_CRUVE_48 rw
  [8n-1497:8n-1504] c{n}_pre (n=188..191)
0x7C0 GAMMA_CRUVE_49 rw
  [8n-1529:8n-1536] c{n}_pre (n=192..195)
0x7C4 GAMMA_CRUVE_50 rw
  [8n-1561:8n-1568] c{n}_pre (n=196..199)
0x7C8 GAMMA_CRUVE_51 rw
  [8n-1593:8n-1600] c{n}_pre (n=200..203)
0x7CC GAMMA_CRUVE_52 rw
  [8n-1625:8n-1632] c{n}_pre (n=204..207)
0x7D0 GAMMA_CRUVE_53 rw
  [8n-1657:8n-1664] c{n}_pre (n=208..211)
0x7D4 GAMMA_CRUVE_54 rw
  [8n-1689:8n-1696] c{n}_pre (n=212..215)
0x7D8 GAMMA_CRUVE_55 rw
  [8n-1721:8n-1728] c{n}_pre (n=216..219)
0x7DC GAMMA_CRUVE_56 rw
  [8n-1753:8n-1760] c{n}_pre (n=220..223)
0x7E0 GAMMA_CRUVE_57 rw
  [8n-1785:8n-1792] c{n}_pre (n=224..227)
0x7E4 GAMMA_CRUVE_58 rw
  [8n-1817:8n-1824] c{n}_pre (n=228..231)
0x7E8 GAMMA_CRUVE_59 rw
  [8n-1849:8n-1856] c{n}_pre (n=232..235)
0x7EC GAMMA_CRUVE_60 rw
  [8n-1881:8n-1888] c{n}_pre (n=236..239)
0x7F0 GAMMA_CRUVE_61 rw
  [8n-1913:8n-1920] c{n}_pre (n=240..243)
0x7F4 GAMMA_CRUVE_62 rw
  [8n-1945:8n-1952] c{n}_pre (n=244..247)
0x7F8 GAMMA_CRUVE_63 rw
  [8n-1977:8n-1984] c{n}_pre (n=248..251)
0x7FC GAMMA_CRUVE_64 rw
  [8n-2009:8n-2016] c{n}_pre (n=252..255)
0x800 BDM_1
  [24:16] g_scal_factor_pre rw, [12:8] gw_thr_pre rw, [0] bdm_eb_pre rw
0x804 BDM_2
  [24:16] b_scal_factor_pre rw, [8:0] r_scal_factor_pre rw
{0x7FC+4i} BDM_{i} (i=3..5)
  [27:16] nr_profile{20i-60:02}_pre rw, [11:0] nr_profile{20i-50}_pre rw
{0x7FC+4i} BDM_{i} (i=6..11)
  [16:0] nr_profile{10i-59:02}_pre rw
{0x7FC+4i} BDM_{i} (i=12..27)
  [24:16] luma_g_w{2i-24}_pre rw, [8:0] luma_g_w{2i-23}_pre rw
{0x800+4i} BDM_{i} (i=28..43)
  [24:16] luma_br_w{2i-56}_pre rw, [8:0] luma_br_w{2i-55}_pre rw
0x8B0 BDM_44
  [15:8] br_corew_pre rw, [7:0] g_corew_pre rw
0x900 WDR_0
  [28:16] wdr_cs_gain_pre rw, [8:4] blwdr_w_cnt_r ro, [1] blwdr_buf_idx_r ro, [0] wdr_en_pre rw
0x904 WDR_CS_0
  [23:16] wdr_cs_grey_th_pre rw, [12:8] wdr_cs_weight_pre rw, [0] wdr_cs_en_pre rw
{0x904+4i} WDR_HIST_{i} (i=1..4)
  [27:24] hist_roi{2i-1}_weight_pre rw, [16] hist_roi{2i-1}_en_pre rw, [11:8] hist_roi{2i-2}_weight_pre rw, [0] hist_roi{2i-2}_en_pre rw
0x918 WDR_HIST_5
  [26:16] hist_x0_min_pre rw, [10:0] hist_x0_max_pre rw
0x91C WDR_HIST_6
  [26:16] hist_y0_min_pre rw, [10:0] hist_y0_max_pre rw
0x920 WDR_HIST_7
  [26:16] hist_x1_min_pre rw, [10:0] hist_x1_max_pre rw
0x924 WDR_HIST_8
  [26:16] hist_y1_min_pre rw, [10:0] hist_y1_max_pre rw
0x928 WDR_HIST_9
  [26:16] hist_x2_min_pre rw, [10:0] hist_x2_max_pre rw
0x92C WDR_HIST_10
  [26:16] hist_y2_min_pre rw, [10:0] hist_y2_max_pre rw
0x930 WDR_HIST_11
  [26:16] hist_x3_min_pre rw, [10:0] hist_x3_max_pre rw
0x934 WDR_HIST_12
  [26:16] hist_y3_min_pre rw, [10:0] hist_y3_max_pre rw
0x938 WDR_HIST_13
  [26:16] hist_x4_min_pre rw, [10:0] hist_x4_max_pre rw
0x93C WDR_HIST_14
  [26:16] hist_y4_min_pre rw, [10:0] hist_y4_max_pre rw
0x940 WDR_HIST_15
  [26:16] hist_x5_min_pre rw, [10:0] hist_x5_max_pre rw
0x944 WDR_HIST_16
  [26:16] hist_y5_min_pre rw, [10:0] hist_y5_max_pre rw
0x948 WDR_HIST_17
  [26:16] hist_x6_min_pre rw, [10:0] hist_x6_max_pre rw
0x94C WDR_HIST_18
  [26:16] hist_y6_min_pre rw, [10:0] hist_y6_max_pre rw
0x950 WDR_HIST_19
  [26:16] hist_x7_min_pre rw, [10:0] hist_x7_max_pre rw
0x954 WDR_HIST_20
  [26:16] hist_y7_min_pre rw, [10:0] hist_y7_max_pre rw
0x958 REG_HIST0_64
  [23:0] hist0_64_r ro
0x95C REG_HIST1_64
  [23:0] hist1_64_r ro
{0xA00+4i} REG_HIST0_{i} (i=0..63)
  [23:0] hist0_{i}_r ro
{0xB00+4i} REG_HIST1_{i} (i=0..63)
  [23:0] hist1_{i}_r ro
{0xBFC+4i} WDR_CURVE_{i} (i=1..32)
  [25:16] curve_{2i-1}_pre rw, [9:0] curve_{2i-2}_pre rw
0xC80 WDR_CURVE_33
  [12:8] curve_weight_pre rw, [0] curve_en_pre rw
0xC84 WDR_ENH_1
  [27:16] enh_y_offset_pre rw, [12:8] enh_weight_pre rw, [0] enh_en_pre rw
0xC88 WDR_ENH_2
  [30:16] enh_y_gain_pre rw, [14:0] enh_c_gain_pre rw
{0xCFC+4i} BL_GAMMA_TABLE_{i} (i=1..128)
  [27:16] gamma_table{2i-1}_pre rw, [11:0] gamma_table{2i-2}_pre rw
0xF00 CC_OFFSET_0
  [31] cc_enable_pre rw, [28:16] cc_pre_offset1_pre rw, [12:0] cc_pre_offset0_pre rw
0xF04 CC_OFFSET_1
  [28:16] cc_post_offset2_pre rw, [12:0] cc_pre_offset2_pre rw
0xF08 CC_OFFSET_2
  [28:16] cc_post_offset1_pre rw, [12:0] cc_post_offset0_pre rw
0xF0C CC_MATRIX_0
  [27:16] cc_matrix01_pre rw, [11:0] cc_matrix00_pre rw
0xF10 CC_MATRIX_1
  [27:16] cc_matrix02_pre rw, [11:0] cc_matrix10_pre rw
0xF14 CC_MATRIX_2
  [27:16] cc_matrix12_pre rw, [11:0] cc_matrix11_pre rw
0xF18 CC_MATRIX_3
  [27:16] cc_matrix21_pre rw, [11:0] cc_matrix20_pre rw
0xF1C CC_CE_MATRIX
  [27:16] ce_matrix02_pre rw, [11:0] cc_matrix22_pre rw
0xF20 CE_MATRIX_0
  [27:16] ce_matrix01_pre rw, [11:0] ce_matrix00_pre rw
0xF24 CE_MATRIX_1
  [27:16] ce_matrix11_pre rw, [11:0] ce_matrix10_pre rw
0xF28 CE_MATRIX_2
  [27:16] ce_matrix12_pre rw, [11:0] ce_matrix20_pre rw
0xF2C CE_MATRIX_3
  [27:16] ce_matrix22_pre rw, [11:0] ce_matrix21_pre rw
0xF30 CE_OFFSET_0
  [28:16] ce_pre_offset1_pre rw, [12:0] ce_pre_offset0_pre rw
0xF34 CE_OFFSET_1
  [28:16] ce_post_offset2_pre rw, [12:0] ce_pre_offset2_pre rw
0xF38 CE_OFFSET_2
  [28:16] ce_post_offset1_pre rw, [12:0] ce_post_offset0_pre rw
